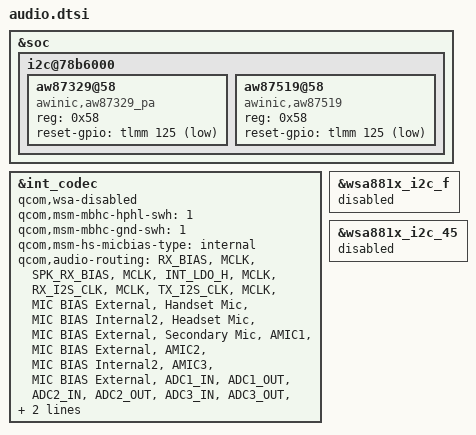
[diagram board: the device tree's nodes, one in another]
&soc {
    i2c@78b6000 {
        aw87329@58 {
            status = "okay";
            compatible = "awinic,aw87329_pa";
            reg = <0x58>;
            reset-gpio = <&tlmm 125 0x01>;
        };

        aw87519@58 {
            status = "okay";
            compatible = "awinic,aw87519";
            reg = <0x58>;
            reset-gpio = <&tlmm 125 0x01>;
        };
    };
};

&int_codec {
    /delete-property/ qcom,msm-micbias2-ext-cap;
    /delete-property/ msm-vdd-wsa-switch-supply;
    /delete-property/ qcom,msm-vdd-wsa-switch-voltage;
    /delete-property/ qcom,msm-vdd-wsa-switch-current;
    /delete-property/ qcom,cdc-us-eu-gpios;
    /delete-property/ qcom,quin-mi2s-gpios;
    /delete-property/ asoc-wsa-codec-names;
    /delete-property/ asoc-wsa-codec-prefixes;
    /delete-property/ msm-vdd-wsa-switch-supply;
    /delete-property/ qcom,msm-vdd-wsa-switch-voltage;
    /delete-property/ qcom,msm-vdd-wsa-switch-current;

    qcom,wsa-disabled;
    
    qcom,msm-mbhc-hphl-swh = <1>;
    qcom,msm-mbhc-gnd-swh = <1>;
    qcom,msm-hs-micbias-type = "internal";

    qcom,audio-routing =
            "RX_BIAS", "MCLK",
            "SPK_RX_BIAS", "MCLK",
            "INT_LDO_H", "MCLK",
            "RX_I2S_CLK", "MCLK",
            "TX_I2S_CLK", "MCLK",
            "MIC BIAS External", "Handset Mic",
            "MIC BIAS Internal2", "Headset Mic",
            "MIC BIAS External", "Secondary Mic",
            "AMIC1", "MIC BIAS External",
            "AMIC2", "MIC BIAS Internal2",
            "AMIC3", "MIC BIAS External",
            "ADC1_IN", "ADC1_OUT",
            "ADC2_IN", "ADC2_OUT",
            "ADC3_IN", "ADC3_OUT",
            "PDM_IN_RX1", "PDM_OUT_RX1",
            "PDM_IN_RX2", "PDM_OUT_RX2",
            "PDM_IN_RX3", "PDM_OUT_RX3";
};

&wsa881x_i2c_f {
	status = "disabled";
};

&wsa881x_i2c_45 {
	status = "disabled";
};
